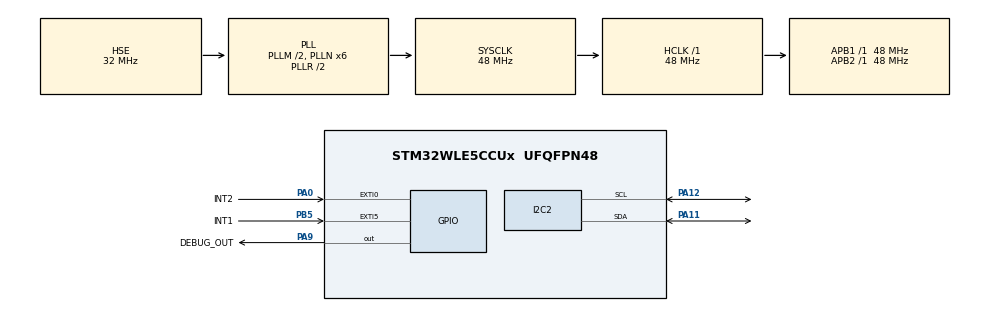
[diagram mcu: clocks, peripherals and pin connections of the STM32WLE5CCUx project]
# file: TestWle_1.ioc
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Dma.I2C2_RX.0.Direction=DMA_PERIPH_TO_MEMORY
Dma.I2C2_RX.0.EventEnable=DISABLE
Dma.I2C2_RX.0.Instance=DMA1_Channel1
Dma.I2C2_RX.0.MemDataAlignment=DMA_MDATAALIGN_BYTE
Dma.I2C2_RX.0.MemInc=DMA_MINC_ENABLE
Dma.I2C2_RX.0.Mode=DMA_NORMAL
Dma.I2C2_RX.0.PeriphDataAlignment=DMA_PDATAALIGN_BYTE
Dma.I2C2_RX.0.PeriphInc=DMA_PINC_DISABLE
Dma.I2C2_RX.0.Polarity=HAL_DMAMUX_REQ_GEN_RISING
Dma.I2C2_RX.0.Priority=DMA_PRIORITY_LOW
Dma.I2C2_RX.0.RequestNumber=1
Dma.I2C2_RX.0.SignalID=NONE
Dma.I2C2_RX.0.SyncEnable=DISABLE
Dma.I2C2_RX.0.SyncPolarity=HAL_DMAMUX_SYNC_NO_EVENT
Dma.I2C2_RX.0.SyncRequestNumber=1
Dma.I2C2_RX.0.SyncSignalID=NONE
Dma.Request0=I2C2_RX
I2C2.Speed=100
I2C2.Timing=0x10805D88
LORAWAN.LORAMAC_CLASSB_ENABLED=true
LORAWAN.LORAMAC_SPECIFICATION_VERSION=0x01000400
LORAWAN.REGION_EU868=false
LORAWAN.USE_LPM=true
LORAWAN.USE_RTC=false
LORAWAN.USE_UART=false
Mcu.Family=STM32WL
Mcu.Name=STM32WLE5CCUx
Mcu.Package=UFQFPN48
NVIC.DMA1_Channel1_IRQn=true\:0\:0\:false\:false\:true\:false\:true\:true
NVIC.EXTI0_IRQn=true\:0\:0\:false\:false\:true\:true\:true\:true
NVIC.EXTI9_5_IRQn=true\:0\:0\:false\:false\:true\:true\:true\:true
NVIC.I2C2_ER_IRQn=true\:0\:0\:false\:false\:true\:true\:true\:true
NVIC.I2C2_EV_IRQn=true\:0\:0\:false\:false\:true\:true\:true\:true
NVIC.PriorityGroup=NVIC_PRIORITYGROUP_4
NVIC.SUBGHZ_Radio_IRQn=true\:0\:0\:false\:false\:true\:true\:true\:true
OSC_IN.Mode=HSE-External-Oscillator
OSC_IN.Signal=RCC_OSC_IN
OSC_OUT.Mode=HSE-External-Oscillator
OSC_OUT.Signal=RCC_OSC_OUT
PA0.GPIO_Label=INT2
PA0.GPIO_ModeDefaultEXTI=GPIO_MODE_IT_RISING
PA0.GPIO_PuPd=GPIO_NOPULL
PA0.Signal=GPXTI0
PA11.Mode=I2C
PA11.Signal=I2C2_SDA
PA12.Mode=I2C
PA12.Signal=I2C2_SCL
PA13.Mode=Serial_Wire
PA13.Signal=DEBUG_JTMS-SWDIO
PA14.Mode=Serial_Wire
PA14.Signal=DEBUG_JTCK-SWCLK
PA9.GPIO_Label=DEBUG_OUT
PA9.Signal=GPIO_Output
PB5.GPIO_Label=INT1
PB5.Signal=GPXTI5
PC14-OSC32_IN.Mode=LSE-External-Oscillator
PC14-OSC32_IN.Signal=RCC_OSC32_IN
PC15-OSC32_OUT.Mode=LSE-External-Oscillator
PC15-OSC32_OUT.Signal=RCC_OSC32_OUT
ProjectManager.HeapSize=0x200
ProjectManager.StackSize=0x400
ProjectManager.TargetToolchain=STM32CubeIDE
RCC.AHBFreq_Value=48000000
RCC.APB1Freq_Value=48000000
RCC.APB1TimFreq_Value=48000000
RCC.APB2Freq_Value=48000000
RCC.APB2TimFreq_Value=48000000
RCC.APB3Freq_Value=48000000
RCC.CortexFreq_Value=48000000
RCC.HCLKFreq_Value=48000000
RCC.HSE_VALUE=32000000
RCC.HSI_VALUE=16000000
RCC.LSE_VALUE=32768
RCC.PLLM=RCC_PLLM_DIV2
RCC.PLLN=6
RCC.PLLSourceVirtual=RCC_PLLSOURCE_HSE
RCC.RTCClockSelection=RCC_RTCCLKSOURCE_LSE
RCC.SYSCLKFreq_VALUE=48000000
RCC.SYSCLKSource=RCC_SYSCLKSOURCE_PLLCLK
RCC.VCOOutputFreq_Value=96000000
RTC.Alarm-Alarm\ A=RTC_ALARM_A
VP_ADV_TRACE_VS_ADV_TRACE.Mode=ADV_TRACE_Enabled
VP_LORAWAN_VS_LoRaWAN.Mode=LoRaWAN_Enabled
VP_MISC_VS_MISC.Mode=MISC_Enabled
VP_RTC_VS_RTC_Activate.Mode=RTC_Enabled
VP_RTC_VS_RTC_Alarm_A_Intern.Mode=Alarm A
VP_RTC_VS_RTC_Calendar.Mode=RTC_Calendar
VP_SEQUENCER_VS_SEQUENCER.Mode=SEQUENCER_Enabled
VP_SUBGHZ_VS_SUBGHZ.Mode=SUBGHZ_Activate
VP_TIMER_VS_TIMER.Mode=TIMER_Enabled
VP_TINY_LPM_VS_TINY_LPM.Mode=TINY_LPM_Enabled
board=custom

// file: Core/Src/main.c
/* USER CODE BEGIN Header */
/**
  ******************************************************************************
  * @file           : main.c
  * @brief          : Main program body
  ******************************************************************************
  * @attention
  *
  * Copyright (c) 2025 STMicroelectronics.
  * All rights reserved.
  *
  * This software is licensed under terms that can be found in the LICENSE file
  * in the root directory of this software component.
  * If no LICENSE file comes with this software, it is provided AS-IS.
  *
  ******************************************************************************
  */
/* USER CODE END Header */
#include "main.h"
#include "app_lorawan.h"

/* USER CODE BEGIN Includes */
#include <string.h>
/* USER CODE END Includes */

I2C_HandleTypeDef hi2c2;
DMA_HandleTypeDef hdma_i2c2_rx;

RTC_HandleTypeDef hrtc;

SUBGHZ_HandleTypeDef hsubghz;

void SystemClock_Config(void);
static void MX_GPIO_Init(void);
static void MX_DMA_Init(void);
static void MX_RTC_Init(void);
static void MX_I2C2_Init(void);
/* USER CODE BEGIN PFP */
extern void StartApplication(void);
/* USER CODE END PFP */

/* USER CODE BEGIN 0 */
//==================================================================================
/**
*  Todo: function description.
*
*  @return void .
*/
//float GetData()
//{
//	uint8_t bufferWr[2];
//	uint8_t bufferRd[2];
//	uint16_t sTemperature;
//	float fTemperature;
//
//
//	bufferWr[0] = TS_I2C_START_MESURE_ADDRESS;
//	bufferWr[1] = TS_I2C_MESURE_MODE;
//	if(HAL_I2C_Master_Transmit(&hi2c2, TS_I2C_DEV_ADDRESS, bufferWr, 2, 100) != HAL_OK)
//	{
//		return(TS_I2C_ERROR_MARKER);
//	}
//
//	HAL_Delay(10);
//
//
//	bufferWr[0] = TS_I2C_RESULT_MESURE_ADDRESS0;
//	if (HAL_I2C_Master_Transmit(&hi2c2, TS_I2C_DEV_ADDRESS, bufferWr, 1, 100) != HAL_OK)
//	{
//		return(TS_I2C_ERROR_MARKER + 1);
//	}
//
//	if (HAL_I2C_Master_Receive(&hi2c2, TS_I2C_DEV_ADDRESS, bufferRd, 1, 100) != HAL_OK)
//	{
//		return(TS_I2C_ERROR_MARKER + 2);
//	}
//
//	bufferWr[0] = TS_I2C_RESULT_MESURE_ADDRESS1;
//	if (HAL_I2C_Master_Transmit(&hi2c2, TS_I2C_DEV_ADDRESS, bufferWr, 1, 100) != HAL_OK)
//	{
//		return(TS_I2C_ERROR_MARKER + 3);
//	}
//
//	if (HAL_I2C_Master_Receive(&hi2c2, TS_I2C_DEV_ADDRESS, &bufferRd[1], 1, 100) != HAL_OK)
//	{
//		return(TS_I2C_ERROR_MARKER + 4);
//	}
//
//	memcpy((void*)&sTemperature, (void*)bufferRd, 2);
//
//	fTemperature = (float)sTemperature / 256 + 25;
//
//
//	return(fTemperature);
//}
//=== end GetData ==================================================================
/* USER CODE END 0 */

int main(void)
{

  /* MCU Configuration--------------------------------------------------------*/

  /* Reset of all peripherals, Initializes the Flash interface and the Systick. */
  HAL_Init();

  /* Configure the system clock */
  SystemClock_Config();

  /* Initialize all configured peripherals */
  MX_GPIO_Init();
  MX_DMA_Init();
  MX_RTC_Init();
  MX_LoRaWAN_Init();
  MX_I2C2_Init();

  /* Infinite loop */
  /* USER CODE BEGIN WHILE */

  ////// never return //////
  StartApplication();

  while (1)
  {
    /* USER CODE END WHILE */
    MX_LoRaWAN_Process();

  }
}

void SystemClock_Config(void)
{
  RCC_OscInitTypeDef RCC_OscInitStruct = {0};
  RCC_ClkInitTypeDef RCC_ClkInitStruct = {0};

  /** Configure LSE Drive Capability
  */
  HAL_PWR_EnableBkUpAccess();
  __HAL_RCC_LSEDRIVE_CONFIG(RCC_LSEDRIVE_LOW);

  /** Configure the main internal regulator output voltage
  */
  __HAL_PWR_VOLTAGESCALING_CONFIG(PWR_REGULATOR_VOLTAGE_SCALE1);

  /** Initializes the CPU, AHB and APB buses clocks
  */
  RCC_OscInitStruct.OscillatorType = RCC_OSCILLATORTYPE_HSE|RCC_OSCILLATORTYPE_LSE;
  RCC_OscInitStruct.HSEState = RCC_HSE_ON;
  RCC_OscInitStruct.LSEState = RCC_LSE_ON;
  RCC_OscInitStruct.HSEDiv = RCC_HSE_DIV1;
  RCC_OscInitStruct.PLL.PLLState = RCC_PLL_ON;
  RCC_OscInitStruct.PLL.PLLSource = RCC_PLLSOURCE_HSE;
  RCC_OscInitStruct.PLL.PLLM = RCC_PLLM_DIV2;
  RCC_OscInitStruct.PLL.PLLN = 6;
  RCC_OscInitStruct.PLL.PLLP = RCC_PLLP_DIV2;
  RCC_OscInitStruct.PLL.PLLR = RCC_PLLR_DIV2;
  RCC_OscInitStruct.PLL.PLLQ = RCC_PLLQ_DIV2;
  if (HAL_RCC_OscConfig(&RCC_OscInitStruct) != HAL_OK)
  {
    Error_Handler();
  }

  /** Configure the SYSCLKSource, HCLK, PCLK1 and PCLK2 clocks dividers
  */
  RCC_ClkInitStruct.ClockType = RCC_CLOCKTYPE_HCLK3|RCC_CLOCKTYPE_HCLK
                              |RCC_CLOCKTYPE_SYSCLK|RCC_CLOCKTYPE_PCLK1
                              |RCC_CLOCKTYPE_PCLK2;
  RCC_ClkInitStruct.SYSCLKSource = RCC_SYSCLKSOURCE_PLLCLK;
  RCC_ClkInitStruct.AHBCLKDivider = RCC_SYSCLK_DIV1;
  RCC_ClkInitStruct.APB1CLKDivider = RCC_HCLK_DIV1;
  RCC_ClkInitStruct.APB2CLKDivider = RCC_HCLK_DIV1;
  RCC_ClkInitStruct.AHBCLK3Divider = RCC_SYSCLK_DIV1;

  if (HAL_RCC_ClockConfig(&RCC_ClkInitStruct, FLASH_LATENCY_2) != HAL_OK)
  {
    Error_Handler();
  }
}

static void MX_I2C2_Init(void)
{

  hi2c2.Instance = I2C2;
  hi2c2.Init.Timing = 0x10805D88;
  hi2c2.Init.OwnAddress1 = 0;
  hi2c2.Init.AddressingMode = I2C_ADDRESSINGMODE_7BIT;
  hi2c2.Init.DualAddressMode = I2C_DUALADDRESS_DISABLE;
  hi2c2.Init.OwnAddress2 = 0;
  hi2c2.Init.OwnAddress2Masks = I2C_OA2_NOMASK;
  hi2c2.Init.GeneralCallMode = I2C_GENERALCALL_DISABLE;
  hi2c2.Init.NoStretchMode = I2C_NOSTRETCH_DISABLE;
  if (HAL_I2C_Init(&hi2c2) != HAL_OK)
  {
    Error_Handler();
  }

  /** Configure Analogue filter
  */
  if (HAL_I2CEx_ConfigAnalogFilter(&hi2c2, I2C_ANALOGFILTER_ENABLE) != HAL_OK)
  {
    Error_Handler();
  }

  /** Configure Digital filter
  */
  if (HAL_I2CEx_ConfigDigitalFilter(&hi2c2, 0) != HAL_OK)
  {
    Error_Handler();
  }

}

static void MX_RTC_Init(void)
{

  RTC_TimeTypeDef sTime = {0};
  RTC_DateTypeDef sDate = {0};
  RTC_AlarmTypeDef sAlarm = {0};

  /** Initialize RTC Only
  */
  hrtc.Instance = RTC;
  hrtc.Init.HourFormat = RTC_HOURFORMAT_24;
  hrtc.Init.AsynchPrediv = 127;
  hrtc.Init.SynchPrediv = 255;
  hrtc.Init.OutPut = RTC_OUTPUT_DISABLE;
  hrtc.Init.OutPutRemap = RTC_OUTPUT_REMAP_NONE;
  hrtc.Init.OutPutPolarity = RTC_OUTPUT_POLARITY_HIGH;
  hrtc.Init.OutPutType = RTC_OUTPUT_TYPE_OPENDRAIN;
  hrtc.Init.OutPutPullUp = RTC_OUTPUT_PULLUP_NONE;
  hrtc.Init.BinMode = RTC_BINARY_NONE;
  if (HAL_RTC_Init(&hrtc) != HAL_OK)
  {
    Error_Handler();
  }

  /** Initialize RTC and set the Time and Date
  */
  sTime.Hours = 0x0;
  sTime.Minutes = 0x0;
  sTime.Seconds = 0x0;
  sTime.DayLightSaving = RTC_DAYLIGHTSAVING_NONE;
  sTime.StoreOperation = RTC_STOREOPERATION_RESET;
  if (HAL_RTC_SetTime(&hrtc, &sTime, RTC_FORMAT_BCD) != HAL_OK)
  {
    Error_Handler();
  }
  sDate.WeekDay = RTC_WEEKDAY_MONDAY;
  sDate.Month = RTC_MONTH_JANUARY;
  sDate.Date = 0x1;
  sDate.Year = 0x0;

  if (HAL_RTC_SetDate(&hrtc, &sDate, RTC_FORMAT_BCD) != HAL_OK)
  {
    Error_Handler();
  }

  /** Enable the Alarm A
  */
  sAlarm.AlarmTime.Hours = 0x0;
  sAlarm.AlarmTime.Minutes = 0x0;
  sAlarm.AlarmTime.Seconds = 0x0;
  sAlarm.AlarmTime.SubSeconds = 0x0;
  sAlarm.AlarmTime.DayLightSaving = RTC_DAYLIGHTSAVING_NONE;
  sAlarm.AlarmTime.StoreOperation = RTC_STOREOPERATION_RESET;
  sAlarm.AlarmMask = RTC_ALARMMASK_NONE;
  sAlarm.AlarmSubSecondMask = RTC_ALARMSUBSECONDMASK_ALL;
  sAlarm.AlarmDateWeekDaySel = RTC_ALARMDATEWEEKDAYSEL_DATE;
  sAlarm.AlarmDateWeekDay = 0x1;
  sAlarm.Alarm = RTC_ALARM_A;
  if (HAL_RTC_SetAlarm(&hrtc, &sAlarm, RTC_FORMAT_BCD) != HAL_OK)
  {
    Error_Handler();
  }

}

void MX_SUBGHZ_Init(void)
{

  hsubghz.Init.BaudratePrescaler = SUBGHZSPI_BAUDRATEPRESCALER_8;
  if (HAL_SUBGHZ_Init(&hsubghz) != HAL_OK)
  {
    Error_Handler();
  }

}

static void MX_DMA_Init(void)
{

  /* DMA controller clock enable */
  __HAL_RCC_DMAMUX1_CLK_ENABLE();
  __HAL_RCC_DMA1_CLK_ENABLE();

  /* DMA interrupt init */
  /* DMA1_Channel1_IRQn interrupt configuration */
  HAL_NVIC_SetPriority(DMA1_Channel1_IRQn, 0, 0);
  HAL_NVIC_EnableIRQ(DMA1_Channel1_IRQn);

}

static void MX_GPIO_Init(void)
{
  GPIO_InitTypeDef GPIO_InitStruct = {0};

  /* GPIO Ports Clock Enable */
  __HAL_RCC_GPIOB_CLK_ENABLE();
  __HAL_RCC_GPIOA_CLK_ENABLE();
  __HAL_RCC_GPIOC_CLK_ENABLE();

  /*Configure GPIO pin Output Level */
  HAL_GPIO_WritePin(DEBUG_OUT_GPIO_Port, DEBUG_OUT_Pin, GPIO_PIN_RESET);

  /*Configure GPIO pin : INT1_Pin */
  GPIO_InitStruct.Pin = INT1_Pin;
  GPIO_InitStruct.Mode = GPIO_MODE_IT_RISING;
  GPIO_InitStruct.Pull = GPIO_NOPULL;
  HAL_GPIO_Init(INT1_GPIO_Port, &GPIO_InitStruct);

  /*Configure GPIO pin : INT2_Pin */
  GPIO_InitStruct.Pin = INT2_Pin;
  GPIO_InitStruct.Mode = GPIO_MODE_IT_RISING;
  GPIO_InitStruct.Pull = GPIO_NOPULL;
  HAL_GPIO_Init(INT2_GPIO_Port, &GPIO_InitStruct);

  /*Configure GPIO pin : DEBUG_OUT_Pin */
  GPIO_InitStruct.Pin = DEBUG_OUT_Pin;
  GPIO_InitStruct.Mode = GPIO_MODE_OUTPUT_PP;
  GPIO_InitStruct.Pull = GPIO_NOPULL;
  GPIO_InitStruct.Speed = GPIO_SPEED_FREQ_LOW;
  HAL_GPIO_Init(DEBUG_OUT_GPIO_Port, &GPIO_InitStruct);

  /* EXTI interrupt init*/
  HAL_NVIC_SetPriority(EXTI0_IRQn, 0, 0);
  HAL_NVIC_EnableIRQ(EXTI0_IRQn);

  HAL_NVIC_SetPriority(EXTI9_5_IRQn, 0, 0);
  HAL_NVIC_EnableIRQ(EXTI9_5_IRQn);

}

void Error_Handler(void)
{
  __disable_irq();
  while (1)
  {
  }
}
